# pse84 register map
Vendor: Cypress Semiconductor; Series: PSE84; File version: 1.0
CPU: CM33 r0p1, little endian, MPU, FPU, VTOR, 3 interrupt priority bits
Registers are 32-bit, read-write, reset 0x0 unless marked. A register's access mark holds for its fields unless they carry their own. Offsets are from the block's base; [hi:lo] are bit positions; lines under a group give offsets from that group; {n}, {i} and the like mark numbered series.

## ACTRLR (part 2 of 3) — Autonomnous Controller
Base 0x42ED0000
{0x800+0x20*i} TTCFG[{i}] (i=0..63) group — Timer Table Structure (only accessible if CTRL.EN=0)
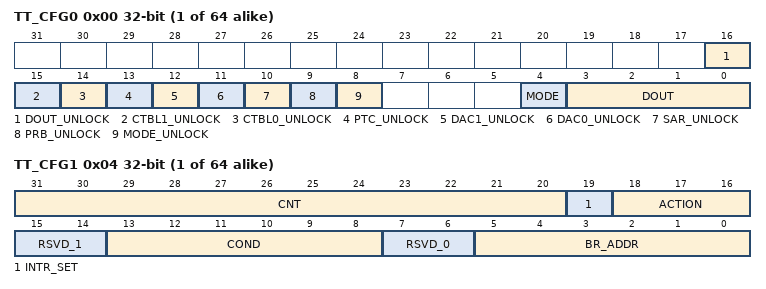
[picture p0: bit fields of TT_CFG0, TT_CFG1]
  0x00 TT_CFG0 — AC Table Configuration 0
    [16] DOUT_UNLOCK — DOUT Unlock 0: Lock: DOUT does NOT get updated 1: Unlock: DOUT does get updated
    [15] CTBL1_UNLOCK — See CTBL0_UNLOCK
    [14] CTBL0_UNLOCK — CTBL0 Unlock 0: Lock: CTBL0 fields: OPA1(0)_EN, OPA1(0)_GAIN, OPA1(0)_CFG do NOT get updated 1: Unlock: CTBL0 fields: OPA1(0)_EN, OPA1(0)_GAIN, OPA1(0)_CFG do get updated
    [13] PTC_UNLOCK — PTC Unlock 0: Lock: PTC fields: CMP1(0)_EN, CMP1(0)_CFG do NOT get updated 1: Unlock: PTC fields: CMP1(0)_EN, CMP1(0)_CFG do get updated
    [12] DAC1_UNLOCK — See DAC0_UNLOCK
    [11] DAC0_UNLOCK — DAC0 Unlock 0: Lock: DAC0 fields: EN does NOT get updated 1: Unlock: DAC0 fields: EN does get updated
    [10] SAR_UNLOCK — SAR Unlock 0: Lock: SAR fields: EN does NOT get updated 1: Unlock: SAR fields: EN does get updated
    [9] PRB_UNLOCK — PRB Unlock 0: Lock: PRB fields: VREF1(0)_VAL, VREF1(0)_FW_MODE do NOT get updated 1: Unlock: PRB fields: VREF1(0)_VAL, VREF1(0)_FW_MODE do get updated
    [8] MODE_UNLOCK — Mode Unlock 0: Lock: MODE does NOT get updated 1: Unlock: MODE does get updated
    [4] MODE — LPPASS Operating Mode 0: High Speed (HS) Operation - The PASS is clocked from CLK_HF directly (nominally 80MHz) and is only functional in chip Active mode (i.e. the IP is reset in chip Deepsleep and Hibernate) 1: Low Power (LP) Operation - The PASS is clocked from CLK_LPOSC (4MHz) and is functional in chip Active and Deepsleep mode (i.e. the IP is only reset in Hibernate)
    [3:0] DOUT — LPPASS data out generation (the corresponding bit in CFG.DOUT_EN must be set when using this field) The data out bus is driven directly to the GPIO HSIO interface. The HSIO interface must be programmed properly for the DOUT bus to be observed on the GPIO pins.
  0x04 TT_CFG1 — AC Table Configuration 1
    [31:20] CNT — This field is used to set the timer/counter values for either interval and loop counts. The actual count is CNT+1. Therefore, the range is 1 to 4096. The value of 1 is degenerate. This field is only valid if the action (ACT) is set to WAIT_FOR, or BRANCH_IF_* and the condition (COND) is set to CNT_DONE. If ACT is set to WAIT_FOR, the counter is first loaded with CNT+1 and is subsequently decremented every clock cycle (clock set by MODE). On terminal count, the CNT_DONE trigger is asserted. If ACT is set to BRANCH_IF_*, the counter is first checked if it is busy (count value is nonzero). If busy, the counter is decremented. If not busy, the counter is loaded with CNT+1. On terminal count, the CNT_DONE trigger is asserted.
    [19] INTR_SET — AC Interrupt Set This field is used for setting the Autonomous Controller Interrupt and/or trigger. When set in a particular state, the AC generates a single cycle pulse to the interrupt logic. The AC interrupt or AC trigger must be unmasked for this field to generate an interrupt/trigger. If ACTION=WAIT_FOR, the signle cycle pulse is generated after the COND occurs, otherwise the single cycle pulse is sent immediately upon entering the state where the field is set.
    [18:16] ACTION — Autonomous Controller Action
      0=STOP (Stop the autonomous controller); 1=NEXT (Proceed to the next state); 2=WAIT_FOR (Wait for the associated COND to occur before moving to the next state If COND=FALSE, stay in the present state indefinitely. If COND=TRUE, move to the next state.); 3=BRANCH_IF_TRUE (Check if COND has occurred, If it has, take the indicated branch (BR ADDR), if not, proceed to the next state. If COND=FALSE, proceed to the next state. If COND=TRUE, take the indicated branch (BR_ADDR).); 4=BRANCH_IF_FALSE (Check if COND has occurred, If it has proceed to the next state, if not, take the indicated branch (BR ADDR) If COND=FALSE, take the indicated branch (BR_ADDR). If COND=TRUE, proceed to the next state.); 5=BRANCH_IF_TRUE_CLR (Check if COND has occurred, If it has, take the indicated branch (BR ADDR), if not, proceed to the next state. If COND=FALSE, proceed to the next state. If COND=TRUE, take the indicated branch (BR_ADDR). If the indicated branch is taken, all loop counters are cleared (reset). If the AC_CONDITION is set to CNT_DONE, then the loop counters are not cleared (reset).); 6=BRANCH_IF_FALSE_CLR (Check if COND has occurred, If it has proceed to the next state, if not, take the indicated branch (BR ADDR) If COND=FALSE, take the indicated branch (BR_ADDR). If COND=TRUE, proceed to the next state. If the indicated branch is taken, all loop counters are cleared (reset). If the AC CONDITION is set to CNT_DONE, then the loop counters are not cleared (reset).); 7=RSVD0 (N/A)
    [15:14] RSVD_1
    [13:8] COND — Autonomous Controller Condition
      0=False (Hardcoded FALSE value); 1=True (Hardcoded TRUE value); 2=BLOCK_READY (Enabled block(s) are ready for use.); 3=CNT_DONE (if the ACTION is WAIT_FOR - this is an interval timer. If the ACTION is BRANCH IF - this is a loop counter.); 4=SAR_DONE (SAR Sequencer Done This status is sticky. It is set by the SAR when finishing a state in the SAR sequencer table (HS or LP) where SAR.SEQ_HS(LP)_DATA.NEXT_STATE is set to STOP. This field should NOT be used if the SAR is configured for CONTINUOUS operation (i.e. SAR.SEQ_HS(LP)_DATA.NEXT_STATE is set to GO_TO_ENTRY_ADDRESS). The status is cleared by the AC when any of the following occur: 1. Executing an AC state where ACT is set to WAIT_FOR or BRANCH_IF_* and COND is set to SAR_DONE. 2. Executing an AC state where ACT is set to WAIT_FOR and COND is set to any of the *_WAKE. 3. Pausing the AC (using the DEBUG_PAUSE or DEBUG_SINGLE_STEP commands) 4. Disabling the AC (through CTRL.ENABLED) 5. Disabling the SAR (by clearing TT_CFG3.SAR_EN) No overflow indication is provided for this bit. Therefore, it is up to the user to program the AC such that this status is read prior to an overflow (multiple SAR_DONEs). This status does NOT indicate that the SAR data has been written to the FIFO (indicated by SAR_FIFO_DONE).); 5=SAR_EOS (SAR Sequencer EOS This status is sticky. It is set by the SAR when finishing the state in the SAR sequencer table (HS or LP) where SAR.SEQ_HS(LP)_DATA.NEXT_STATE is set to GO_TO_ENTRY_ADDRESS or STOP. The status is cleared by the AC when executing an AC state with the COND programmed to SAR_EOS. No overflow indication is provided for this bit. Therefore, it is up to the user to program the AC such that this status is read prior to an overflow (multiple SAR_EOSs). The status is cleared by the AC when any of the following occur: 1. Executing an AC state where ACT is set to WAIT_FOR or BRANCH_IF_* and COND is set to SAR_EOS. 2. Executing an AC state where ACT is set to WAIT_FOR and COND is set to any of the *_WAKE. 3. Pausing the AC (using the DEBUG_PAUSE or DEBUG_SINGLE_STEP commands) 4. Disabling the AC (through CTRL.ENABLED) 5. Disabling the SAR (by clearing TT_CFG3.SAR_EN) No overflow indication is provided for this bit. Therefore, it is up to the user to program the AC such that this status is read prior to an overflow (multiple SAR_EOSs).); 6=SAR_RANGE0 (SAR Range 0 detection This status is sticky. It is set by the SAR if the RANGE0 condition is met for a given channel with range 0 status enabled (i.e. SAR_STA_CFG.GPIO(MUX)_CHAN_CFG.STATUS_SEL=STATUS_STRUCT_0). The status is cleared by the AC when any of the following occur: 1. Executing an AC state where ACT is set to WAIT_FOR or BRANCH_IF_* and COND is set to SAR_RANGE0. 2. Executing an AC state where ACT is set to WAIT_FOR and COND is set to any of the *_WAKE. 3. Pausing the AC (using the DEBUG_PAUSE or DEBUG_SINGLE_STEP commands) 4. Disabling the AC (through CTRL.ENABLED) 5. Disabling the SAR (by clearing TT_CFG3.SAR_EN) No overflow indication is provided for this bit. Therefore, it is up to the user to program the AC such that this status is read prior to an overflow (multiple SAR_RANGE0s).); 7=SAR_RANGE1 (SAR Range 1 detection This status is sticky. It is set by the SAR if the RANGE0 condition is met for a given channel with range 1 status enabled (i.e. SAR_STA_CFG.GPIO(MUX)_CHAN_CFG.STATUS_SEL=STATUS_STRUCT_1). The status is cleared by the AC when any of the following occur: 1. Executing an AC state where ACT is set to WAIT_FOR or BRANCH_IF_* and COND is set to SAR_RANGE1. 2. Executing an AC state where ACT is set to WAIT_FOR and COND is set to any of the *_WAKE. 3. Pausing the AC (using the DEBUG_PAUSE or DEBUG_SINGLE_STEP commands) 4. Disabling the AC (through CTRL.ENABLED) 5. Disabling the SAR (by clearing TT_CFG3.SAR_EN) No overflow indication is provided for this bit. Therefore, it is up to the user to program the AC such that this status is read prior to an overflow (multiple SAR_RANGE0s).); 8=SAR_RANGE2 (SAR Range 2 detection This status is sticky. It is set by the SAR if the RANGE2 condition is met for a given channel with range 0 status enabled (i.e. SAR_STA_CFG.GPIO(MUX)_CHAN_CFG.STATUS_SEL=STATUS_STRUCT_2). The status is cleared by the AC when any of the following occur: 1. Executing an AC state where ACT is set to WAIT_FOR or BRANCH_IF_* and COND is set to SAR_RANGE2. 2. Executing an AC state where ACT is set to WAIT_FOR and COND is set to any of the *_WAKE. 3. Pausing the AC (using the DEBUG_PAUSE or DEBUG_SINGLE_STEP commands) 4. Disabling the AC (through CTRL.ENABLED) 5. Disabling the SAR (by clearing TT_CFG3.SAR_EN) No overflow indication is provided for this bit. Therefore, it is up to the user to program the AC such that this status is read prior to an overflow (multiple SAR_RANGE2s).); 9=SAR_RANGE3 (SAR Range 3 detection This status is sticky. It is set by the SAR if the RANGE0 condition is met for a given channel with range 3 status enabled (i.e. SAR_STA_CFG.GPIO(MUX)_CHAN_CFG.STATUS_SEL=STATUS_STRUCT_3). The status is cleared by the AC when any of the following occur: 1. Executing an AC state where ACT is set to WAIT_FOR or BRANCH_IF_* and COND is set to SAR_RANGE3. 2. Executing an AC state where ACT is set to WAIT_FOR and COND is set to any of the *_WAKE. 3. Pausing the AC (using the DEBUG_PAUSE or DEBUG_SINGLE_STEP commands) 4. Disabling the AC (through CTRL.ENABLED) 5. Disabling the SAR (by clearing TT_CFG3.SAR_EN) No overflow indication is provided for this bit. Therefore, it is up to the user to program the AC such that this status is read prior to an overflow (multiple SAR_RANGE3s).); 10=SAR_BUSY (SAR BUSY detection This status is set whenever the SAR is running a scan. This status is transparent from the SAR sequencer (i.e. the status is not sticky).); 11=SAR_FIR0_DONE (SAR FIR0 Done detection This status is sticky. It is set by the SAR FIR0 block whenever FIR0 produces a valid output. The status is cleared by the AC when any of the following occur: 1. Executing an AC state where ACT is set to WAIT_FOR or BRANCH_IF_* and COND is set to SAR_RANGE3. 2. Executing an AC state where ACT is set to WAIT_FOR and COND is set to any of the *_WAKE. 3. Pausing the AC (using the DEBUG_PAUSE or DEBUG_SINGLE_STEP commands) 4. Disabling the AC (through CTRL.ENABLED) 5. Disabling the SAR (by clearing TT_CFG3.SAR_EN) The status is cleared by the AC when executing an AC state with the COND programmed to SAR_FIR0_DONE. No overflow indication is provided for this bit. Therefore, it is up to the user to program the AC such that this status is read prior to an overflow (multiple SAR_FIR0_DONEs). This status does NOT indicate that the FIR0 data has been written to the FIFO (indicated by SAR_FIR0_FIFO_DONE).); 12=SAR_FIR1_DONE (SAR FIR1 Done detection This status is sticky. It is set by the SAR FIR1 block whenever FIR0 produces a valid output. The status is cleared by the AC when any of the following occur: 1. Executing an AC state where ACT is set to WAIT_FOR or BRANCH_IF_* and COND is set to SAR_RANGE3. 2. Executing an AC state where ACT is set to WAIT_FOR and COND is set to any of the *_WAKE. 3. Pausing the AC (using the DEBUG_PAUSE or DEBUG_SINGLE_STEP commands) 4. Disabling the AC (through CTRL.ENABLED) 5. Disabling the SAR (by clearing TT_CFG3.SAR_EN) The status is cleared by the AC when executing an AC state with the COND programmed to SAR_FIR1_DONE. No overflow indication is provided for this bit. Therefore, it is up to the user to program the AC such that this status is read prior to an overflow (multiple SAR_FIR1_DONEs). This status does NOT indicate that the FIR1 data has been written to the FIFO (indicated by SAR_FIR1_FIFO_DONE).); 13=SAR_FIFO_DONE (SAR FIFO Done This status is sticky. This status is SAR_DONE ANDED with FIFO writing complete. This field should NOT be used if the SAR is configured for CONTINUOUS operation (i.e. SAR.SEQ_HS(LP)_DATA.NEXT_STATE is set to GO_TO_ENTRY_ADDRESS) since SAR_DONE is never asserted. In that case, the user should use the appropriate FIFO_LEVEL triggers. The status is cleared by the AC when any of the following occur: 1. Executing an AC state where ACT is set to WAIT_FOR or BRANCH_IF_* and COND is set to SAR_FIFO_DONE. 2. Executing an AC state where ACT is set to WAIT_FOR and COND is set to any of the *_WAKE. 3. Pausing the AC (using the DEBUG_PAUSE or DEBUG_SINGLE_STEP commands) 4. Disabling the AC (through CTRL.ENABLED) 5. Disabling the SAR (by clearing TT_CFG3.SAR_EN) No overflow indication is provided for this bit. Therefore, it is up to the user to program the AC such that this status is read prior to an overflow (multiple SAR_FIFO_DONEs). This status does NOT indicate that the SAR data has been written to the FIFO (indicated by SAR_FIFO_DONE).); 14=SAR_FIR0_FIFO_DONE (SAR FIR0 FIFO Done detection This status is sticky. It is set by the SAR FIR0 block whenever FIR0 data has been written into the FIFO. When using this bit, it is expected that FIR0 writes to the FIFO only once in a given SAR scan. The status is cleared by the AC when any of the following occur: 1. Executing an AC state where ACT is set to WAIT_FOR or BRANCH_IF_* and COND is set to SAR_FIR0_FIFO_DONE. 2. Executing an AC state where ACT is set to WAIT_FOR and COND is set to any of the *_WAKE. 3. Pausing the AC (using the DEBUG_PAUSE or DEBUG_SINGLE_STEP commands) 4. Disabling the AC (through CTRL.ENABLED) 5. Disabling the SAR (by clearing TT_CFG3.SAR_EN) No overflow indication is provided for this bit. Therefore, it is up to the user to program the AC such that this status is read prior to an overflow (multiple SAR_FIR0_FIFO_DONEs).); 15=SAR_FIR1_FIFO_DONE (SAR FIR1 FIFO Done detection This status is sticky. It is set by the SAR FIR1 block whenever FIR1 data has been written into the FIFO. When using this bit, it is expected that FIR1 writes to the FIFO only once in a given SAR scan. The status is cleared by the AC when any of the following occur: 1. Executing an AC state where ACT is set to WAIT_FOR or BRANCH_IF_* and COND is set to SAR_FIR1_FIFO_DONE. 2. Executing an AC state where ACT is set to WAIT_FOR and COND is set to any of the *_WAKE. 3. Pausing the AC (using the DEBUG_PAUSE or DEBUG_SINGLE_STEP commands) 4. Disabling the AC (through CTRL.ENABLED) 5. Disabling the SAR (by clearing TT_CFG3.SAR_EN) No overflow indication is provided for this bit. Therefore, it is up to the user to program the AC such that this status is read prior to an overflow (multiple SAR_FIR1_FIFO_DONEs).); 16=PTC_STROBE0 (PTC Post Processor 0 Strobe This status is set whenever the PTC Post Processor 0 has valid data. This status is transparent from the PTC post processor (i.e. the status is not sticky). The AC needs to poll this status (i.e. ACTION is WAIT_FOR and COND is PTC_STROBE0) prior to checking PTC_RANGE0.); 17=PTC_STROBE1 (PTC Post Processor 1 Strobe This status is set whenever the PTC Post Processor 1 has valid data. This status is transparent from the PTC post processor (i.e. the status is not sticky). The AC needs to poll this status (i.e. ACTION is WAIT_FOR and COND is PTC_STROBE1) prior to checking PTC_RANGE1.); 18=PTC_CMP0 (PTC COMP0 output This status is sticky. It is set by the PTC Comparator 0 if the condition is met (i.e. PTC_STA_CFG.CFG.COMP0_OUT field). The status is cleared by the AC when any of the following occur: 1. Executing an AC state where ACT is set to WAIT_FOR or BRANCH_IF_* and COND is set to PTC_CMP0. 2. Executing an AC state where ACT is set to WAIT_FOR and COND is set to any of the *_WAKE. 3. Pausing the AC (using the DEBUG_PAUSE or DEBUG_SINGLE_STEP commands) 4. Disabling the AC (through CTRL.ENABLED) 5. Disabling PTC comparator 1 (by clearing TT_CFG3.PTC_CMP0_EN) No overflow indication is provided for this bit. Therefore, it is up to the user to program the AC such that this status is read prior to an overflow (multiple PTC_CMP0s).); 19=PTC_CMP1 (PTC COMP1 output This status is sticky. It is set by the PTC Comparator 1 if the condition is met (i.e. PTC_STA_CFG.CFG.COMP1_OUT field). The status is cleared by the AC when any of the following occur: 1. Executing an AC state where ACT is set to WAIT_FOR or BRANCH_IF_* and COND is set to PTC_CMP1. 2. Executing an AC state where ACT is set to WAIT_FOR and COND is set to any of the *_WAKE. 3. Pausing the AC (using the DEBUG_PAUSE or DEBUG_SINGLE_STEP commands) 4. Disabling the AC (through CTRL.ENABLED) 5. Disabling PTC comparator 1 (by clearing TT_CFG3.PTC_CMP1_EN) No overflow indication is provided for this bit. Therefore, it is up to the user to program the AC such that this status is read prior to an overflow (multiple PTC_CMP1s).); 20=PTC_RANGE0 (PTC Post Processor 0 Range output This status is sticky. It is set by the PTC Post Processor if the RANGE0 condition is met (i.e. PTC_PP_STRUCT0.*). The status is cleared by the AC when any of the following occur: 1. Executing an AC state where ACT is set to WAIT_FOR or BRANCH_IF_* and COND is set to SAR_FIR1_FIFO_DONE. 2. Executing an AC state where ACT is set to WAIT_FOR and COND is set to any of the *_WAKE. 3. Pausing the AC (using the DEBUG_PAUSE or DEBUG_SINGLE_STEP commands) 4. Disabling the AC (through CTRL.ENABLED) 5. Disabling both PTC comparators (by clearing TT_CFG3.PTC_CMP0_EN AND TT_CFG3_PTC_COMP1_EN) No overflow indication is provided for this bit. Therefore, it is up to the user to program the AC such that this status is read prior to an overflow (multiple PTC_RANGE0s).); 21=PTC_RANGE1 (PTC Post Processor 1 Range output This status is sticky. It is set by the PTC Post Processor if the RANGE1 condition is met (i.e. PTC_PP_STRUCT1.*). The status is cleared by the AC when any of the following occur: 1. Executing an AC state where ACT is set to WAIT_FOR or BRANCH_IF_* and COND is set to SAR_FIR1_FIFO_DONE. 2. Executing an AC state where ACT is set to WAIT_FOR and COND is set to any of the *_WAKE. 3. Pausing the AC (using the DEBUG_PAUSE or DEBUG_SINGLE_STEP commands) 4. Disabling the AC (through CTRL.ENABLED) 5. Disabling both PTC comparators (by clearing TT_CFG3.PTC_CMP0_EN AND TT_CFG3_PTC_COMP1_EN) No overflow indication is provided for this bit. Therefore, it is up to the user to program the AC such that this status is read prior to an overflow (multiple PTC_RANGE1s).); 22=CTBL0_CMP0 (CTBL0 COMP0 output This status is sticky. It is set by the CTBL0 Opamp0 Comparator if the condition is met (i.e. CTBL_STA_CFG.CFG.COMP0_OUT field). The status is cleared by the AC when any of the following occur: 1. Executing an AC state where ACT is set to WAIT_FOR or BRANCH_IF_* and COND is set to CTBL0_CMP0. 2. Executing an AC state where ACT is set to WAIT_FOR and COND is set to any of the *_WAKE. 3. Pausing the AC (using the DEBUG_PAUSE or DEBUG_SINGLE_STEP commands) 4. Disabling the AC (through CTRL.ENABLED) 5. Disabling CTBL0 opamp0 (by clearing TT_CFG2.CTBL0_OA0_EN) No overflow indication is provided for this bit. Therefore, it is up to the user to program the AC such that this status is read prior to an overflow (multiple CTBL0_CMP0s).); 23=CTBL0_CMP1 (CTBL0 COMP1 output This status is sticky. It is set by the CTBL0 Opamp1 Comparator if the condition is met (i.e. CTBL_STA_CFG.CFG.COMP1_OUT field). The status is cleared by the AC when any of the following occur: 1. Executing an AC state where ACT is set to WAIT_FOR or BRANCH_IF_* and COND is set to CTBL0_CMP1. 2. Executing an AC state where ACT is set to WAIT_FOR and COND is set to any of the *_WAKE. 3. Pausing the AC (using the DEBUG_PAUSE or DEBUG_SINGLE_STEP commands) 4. Disabling the AC (through CTRL.ENABLED) 5. Disabling CTBL0 opamp1 (by clearing TT_CFG2.CTBL0_OA1_EN) No overflow indication is provided for this bit. Therefore, it is up to the user to program the AC such that this status is read prior to an overflow (multiple CTBL0_CMP1s).); 24=CTBL1_CMP0 (CTBL1 COMP0 output This status is sticky. It is set by the CTBL1 Opamp0 Comparator if the condition is met (i.e. CTBL_STA_CFG.CFG.COMP0_OUT field). The status is cleared by the AC when any of the following occur: 1. Executing an AC state where ACT is set to WAIT_FOR or BRANCH_IF_* and COND is set to CTBL1_CMP0. 2. Executing an AC state where ACT is set to WAIT_FOR and COND is set to any of the *_WAKE. 3. Pausing the AC (using the DEBUG_PAUSE or DEBUG_SINGLE_STEP commands) 4. Disabling the AC (through CTRL.ENABLED) 5. Disabling CTBL1 opamp0 (by clearing TT_CFG2.CTBL0_OA0_EN) No overflow indication is provided for this bit. Therefore, it is up to the user to program the AC such that this status is read prior to an overflow (multiple CTBL1_CMP0s).); 25=CTBL1_CMP1 (CTBL1 COMP1 output This status is sticky. It is set by the CTBL1 Opamp1 Comparator if the condition is met (i.e. CTBL_STA_CFG.CFG.COMP1_OUT field). The status is cleared by the AC when any of the following occur: 1. Executing an AC state where ACT is set to WAIT_FOR or BRANCH_IF_* and COND is set to CTBL1_CMP1. 2. Executing an AC state where ACT is set to WAIT_FOR and COND is set to any of the *_WAKE. 3. Pausing the AC (using the DEBUG_PAUSE or DEBUG_SINGLE_STEP commands) 4. Disabling the AC (through CTRL.ENABLED) 5. Disabling CTBL1 opamp1 (by clearing TT_CFG2.CTBL0_OA1_EN) No overflow indication is provided for this bit. Therefore, it is up to the user to program the AC such that this status is read prior to an overflow (multiple CTBL1_CMP1s).); {v}=RSVD{v-26} (N/A) (v=26..31); 32=CHIP_ACTIVE_MODE (Chip Active Mode Status This status is set whenever the system is operating in Active Mode (this includes all Low Power active modes)); 33=CHIP_DEEPSLEEP_MODE (Chip Deepsleep Mode Status This status is set whenever the system is operating in Deepsleep Mode (this includes all RAM power modes in Deepsleep)); {v}=TR_LPPASS_IN{v-34} (External trigger 0 (or the FW trigger {v-34}) This status is sticky. It is set by the either the external hardware trigger 0 or FW trigger {v-34} asserting. The status is cleared by the AC when any of the following occur: 1. Executing an AC state where ACT is set to WAIT_FOR or BRANCH_IF_* and COND is set to TR_LPPASS_IN{v-34}. 2. Executing an AC state where ACT is set to WAIT_FOR and COND is set to any of the *_WAKE. 3. Pausing the AC (using the DEBUG_PAUSE or DEBUG_SINGLE_STEP commands) 4. Disabling the AC (through CTRL.ENABLED) No overflow indication is provided for this bit. Therefore, it is up to the user to program the AC such that this status is read prior to an overflow (multiple TR_LPPASS_IN{v-34}s).) (v=34..37); 38=TR_LPPASS_IN_WAKE (External Trigger Wakeup Source When using this condition, the action (ACT) must be set to WAIT_FOR. This condition is used to put the AC to sleep. The AC will wake from sleep when any external trigger [0-3] is asserted. When the AC is sleeping, all registered AC conditions are cleared.); 39=TIMER_DONE_WAKE (Timer Wakeup Source When using this condition, the action (ACT) must be set to WAIT_FOR. The Wakeup Timer must also be configured (INFRA.TIMER registers). This condition is used to put the AC to sleep. The AC will wake from sleep when the Wakeup Timer reaches terminal count (TC). When the AC is sleeping, all registered AC conditions are cleared.); 40=CTBL0_CMP0_WAKE (CTBL0 comparator 0 wakeup When using this condition, the action (ACT) must be set to WAIT_FOR. The comparator wakeup condition is configured per CTBL0_STA_CFG_Regs.CFG.OA0_COMP_OUT. The CTBL0 comparator 0 be enabled during sleep (TT_CFG2.CTBL0_OA0_EN=1). This condition is used to put the AC to sleep. The AC will wake from sleep when CTBL0 Comparator 0 meets the configured wakeup condition. When the AC is sleeping, all registered AC conditions are cleared.); 41=CTBL0_CMP1_WAKE (CTBL0 comparator 1 wakeup When using this condition, the action (ACT) must be set to WAIT_FOR. The comparator wakeup condition is configured per CTBL0_STA_CFG_Regs.CFG.OA0_COMP_OUT. The CTBL0 comparator 1 be enabled during sleep (TT_CFG2.CTBL0_OA1_EN=1). This condition is used to put the AC to sleep. The AC will wake from sleep when CTBL0 Comparator 1 meets the configured wakeup condition. When the AC is sleeping, all registered AC conditions are cleared.); 42=CTBL1_CMP0_WAKE (CTBL1 comparator 0 wakeup When using this condition, the action (ACT) must be set to WAIT_FOR. The comparator wakeup condition is configured per CTBL1_STA_CFG_Regs.CFG.OA0_COMP_OUT. The CTBL1 comparator 0 be enabled during sleep (TT_CFG2.CTBL1_OA0_EN=1). This condition is used to put the AC to sleep. The AC will wake from sleep due when CTBL1 Comparator 0 meets the configured wkaeup condition. When the AC is sleeping, all registered AC conditions are cleared.); 43=CTBL1_CMP1_WAKE (CTBL1 comparator 1 wakeup When using this condition, the action (ACT) must be set to WAIT_FOR. The comparator wakeup condition is configured per CTBL1_STA_CFG_Regs.CFG.OA0_COMP_OUT. The CTBL1 comparator 1 be enabled during sleep (TT_CFG2.CTBL1_OA1_EN=1). This condition is used to put the AC to sleep. The AC will wake from sleep when CTBL1 Comparator 1 meets the configured wakeup condition. When the AC is sleeping, all registered AC conditions are cleared.); 44=PTC_CMP0_WAKE (PTC comparator 0 wakeup When using this condition, the action (ACT) must be set to WAIT_FOR. The comparator wakeup condition is configured per PTC_STA_CFG_Regs.CFG.COMP0_OUT. The PTC comparator 0 be enabled during sleep (TT_CFG3.PTC_CMP0_EN=1). This condition is used to put the AC to sleep. The AC will wake from sleep when PTC Comparator 0 meets the configured wakeup condition. When the AC is sleeping, all registered AC conditions are cleared.); 45=PTC_CMP1_WAKE (PTC comparator 1 wakeup When using this condition, the action (ACT) must be set to WAIT_FOR. The comparator wakeup condition is configured per PTC_STA_CFG_Regs.CFG.COMP1_OUT. The PTC comparator 0 be enabled during sleep (TT_CFG3.PTC_CMP1_EN=1). This condition is used to put the AC to sleep. The AC will wake from sleep when PTC Comparator 1 meets the configured wakeup condition. When the AC is sleeping, all registered AC conditions are cleared.); 46=FIFO_LEVEL0 (FIFO Level 0 trigger This status is set whenever FIFO0 level condition has been met (FIFO_LEVEL0.LEVEL). This status is transparent from the FIFO (i.e. the status is not sticky).); 47=FIFO_LEVEL1 (FIFO Level 1 trigger This status requires that FIFO_STA_CFG_Regs.CFG.SEL=1,2,3. This status is set whenever FIFO1 level condition has been met (FIFO_LEVEL1.LEVEL). This status is transparent from the FIFO (i.e. the status is not sticky).); 48=FIFO_LEVEL2 (FIFO Level 2 trigger This status requires that FIFO_STA_CFG_Regs.CFG.SEL=2,3. This status is set whenever FIFO2 level condition has been met (FIFO_LEVEL2.LEVEL). This status is transparent from the FIFO (i.e. the status is not sticky).); 49=FIFO_LEVEL3 (FIFO Level 3 trigger This status requires that FIFO_STA_CFG_Regs.CFG.SEL=2,3. This status is set whenever FIFO3 level condition has been met (FIFO_LEVEL3.LEVEL). This status is transparent from the FIFO (i.e. the status is not sticky).); {v}=FIFO_LEVEL{v-46} (FIFO Level {v-46} trigger This status requires that FIFO_STA_CFG_Regs.CFG.SEL=3. This status is set whenever FIFO{v-46} level condition has been met (FIFO_LEVEL{v-46}.LEVEL). This status is transparent from the FIFO (i.e. the status is not sticky).) (v=50..53); 54=DAC0_RANGE0 (DAC0 Range 0 detection This status is sticky. It is set by the DAC0 if the RANGE0 condition is met for a given channel with range 0 status enabled (i.e. DAC0_STA_CFG.CHAN_CFG.STATUS_SEL=STATUS_0). This status is not used when DAC0 is configured for FW mode. The status is cleared by the AC when any of the following occur: 1. Executing an AC state where ACT is set to WAIT_FOR or BRANCH_IF_* and COND is set to DAC0_RANGE0. 2. Executing an AC state where ACT is set to WAIT_FOR and COND is set to any of the *_WAKE. 3. Pausing the AC (using the DEBUG_PAUSE or DEBUG_SINGLE_STEP commands) 4. Disabling the AC (through CTRL.ENABLED) 5. Disabling the DAC0 (by clearing TT_CFG3.DAC0_EN) No overflow indication is provided for this bit. Therefore, it is up to the user to program the AC such that this status is read prior to an overflow (multiple DAC0_RANGE0s).); 55=DAC0_RANGE1 (DAC0 Range 1 detection This status is sticky. It is set by the DAC0 if the RANGE1 condition is met for a given channel with range 1 status enabled (i.e. DAC0_STA_CFG.CHAN_CFG.STATUS_SEL=STATUS_1). This status is not used when DAC0 is configured for FW mode. The status is cleared by the AC when any of the following occur: 1. Executing an AC state where ACT is set to WAIT_FOR or BRANCH_IF_* and COND is set to DAC0_RANGE1. 2. Executing an AC state where ACT is set to WAIT_FOR and COND is set to any of the *_WAKE. 3. Pausing the AC (using the DEBUG_PAUSE or DEBUG_SINGLE_STEP commands) 4. Disabling the AC (through CTRL.ENABLED) 5. Disabling the DAC0 (by clearing TT_CFG3.DAC0_EN) No overflow indication is provided for this bit. Therefore, it is up to the user to program the AC such that this status is read prior to an overflow (multiple DAC0_RANGE1s).); 56=DAC0_RANGE2 (DAC0 Range 2 detection This status is sticky. It is set by the DAC0 if the RANGE2 condition is met for a given channel with range 2 status enabled (i.e. DAC0_STA_CFG.CHAN_CFG.STATUS_SEL=STATUS_2). This status is not used when DAC0 is configured for FW mode. The status is cleared by the AC when any of the following occur: 1. Executing an AC state where ACT is set to WAIT_FOR or BRANCH_IF_* and COND is set to DAC0_RANGE2. 2. Executing an AC state where ACT is set to WAIT_FOR and COND is set to any of the *_WAKE. 3. Pausing the AC (using the DEBUG_PAUSE or DEBUG_SINGLE_STEP commands) 4. Disabling the AC (through CTRL.ENABLED) 5. Disabling the DAC0 (by clearing TT_CFG3.DAC0_EN) No overflow indication is provided for this bit. Therefore, it is up to the user to program the AC such that this status is read prior to an overflow (multiple DAC0_RANGE2s).); 57=DAC0_EPOCH (DAC0 End of Waveform event This status is sticky. It is set by the DAC when finishing a waveform. This condition is only used if the DAC channel (pointed to by the AC when triggered) is configured for LUT mode. The status is cleared by the AC when any of the following occur: 1. Executing an AC state where ACT is set to WAIT_FOR or BRANCH_IF_* and COND is set to DAC0_EPOCH. 2. Executing an AC state where ACT is set to WAIT_FOR and COND is set to any of the *_WAKE. 3. Pausing the AC (using the DEBUG_PAUSE or DEBUG_SINGLE_STEP commands) 4. Disabling the AC (through CTRL.ENABLED) 5. Disabling the SAR (by clearing TT_CFG3.DAC0_EN) No overflow indication is provided for this bit. Therefore, it is up to the user to program the AC such that this status is read prior to an overflow (multiple DAC0_EPOCHs).); 58=DAC0_STROBE (DAC0 Strobe This status is set whenever the DAC output has been updated. This status is typically used by the AC to poll when the DAC has responded to the DAC_INC/DAC_DEC fields.This status is transparent from the DAC (i.e. the status is not sticky). The AC needs to poll this status (i.e. ACTION is WAIT_FOR and COND is DAC0_STROBE) prior to checking DAC_RANGE0-2 or setting DAC_INC/DAC_DEC fields.); 59=DAC1_RANGE0 (DAC1 Range 0 detection This status is sticky. It is set by the DAC1 if the RANGE0 condition is met for a given channel with range 0 status enabled (i.e. DAC1_STA_CFG.CHAN_CFG.STATUS_SEL=STATUS_0). The status is cleared by the AC when any of the following occur: 1. Executing an AC state where ACT is set to WAIT_FOR or BRANCH_IF_* and COND is set to DAC1_RANGE0. 2. Executing an AC state where ACT is set to WAIT_FOR and COND is set to any of the *_WAKE. 3. Pausing the AC (using the DEBUG_PAUSE or DEBUG_SINGLE_STEP commands) 4. Disabling the AC (through CTRL.ENABLED) 5. Disabling the DAC1 (by clearing TT_CFG3.DAC1_EN) No overflow indication is provided for this bit. Therefore, it is up to the user to program the AC such that this status is read prior to an overflow (multiple DAC1_RANGE0s).); 60=DAC1_RANGE1 (DAC1 Range 1 detection This status is sticky. It is set by the DAC0 if the RANGE1 condition is met for a given channel with range 1 status enabled (i.e. DAC1_STA_CFG.CHAN_CFG.STATUS_SEL=STATUS_1). The status is cleared by the AC when any of the following occur: 1. Executing an AC state where ACT is set to WAIT_FOR or BRANCH_IF_* and COND is set to DAC1_RANGE1. 2. Executing an AC state where ACT is set to WAIT_FOR and COND is set to any of the *_WAKE. 3. Pausing the AC (using the DEBUG_PAUSE or DEBUG_SINGLE_STEP commands) 4. Disabling the AC (through CTRL.ENABLED) 5. Disabling the DAC1 (by clearing TT_CFG3.DAC1_EN) No overflow indication is provided for this bit. Therefore, it is up to the user to program the AC such that this status is read prior to an overflow (multiple DAC1_RANGE1s).); 61=DAC1_RANGE2 (DAC1 Range 2 detection This status is sticky. It is set by the DAC1 if the RANGE2 condition is met for a given channel with range 2 status enabled (i.e. DAC1_STA_CFG.CHAN_CFG.STATUS_SEL=STATUS_2). The status is cleared by the AC when any of the following occur: 1. Executing an AC state where ACT is set to WAIT_FOR or BRANCH_IF_* and COND is set to DAC1_RANGE2. 2. Executing an AC state where ACT is set to WAIT_FOR and COND is set to any of the *_WAKE. 3. Pausing the AC (using the DEBUG_PAUSE or DEBUG_SINGLE_STEP commands) 4. Disabling the AC (through CTRL.ENABLED) 5. Disabling the DAC1 (by clearing TT_CFG3.DAC1_EN) No overflow indication is provided for this bit. Therefore, it is up to the user to program the AC such that this status is read prior to an overflow (multiple DAC1_RANGE2s).); 62=DAC1_EPOCH (DAC1 End of Waveform event This status is sticky. It is set by the DAC when finishing a waveform. This condition is only used if the DAC channel (pointed to by the AC when triggered) is configured for LUT mode. The status is cleared by the AC when any of the following occur: 1. Executing an AC state where ACT is set to WAIT_FOR or BRANCH_IF_* and COND is set to DAC1_EPOCH. 2. Executing an AC state where ACT is set to WAIT_FOR and COND is set to any of the *_WAKE. 3. Pausing the AC (using the DEBUG_PAUSE or DEBUG_SINGLE_STEP commands) 4. Disabling the AC (through CTRL.ENABLED) 5. Disabling the SAR (by clearing TT_CFG3.DAC1_EN) No overflow indication is provided for this bit. Therefore, it is up to the user to program the AC such that this status is read prior to an overflow (multiple DAC1_EPOCHs).); 63=DAC1_STROBE (DAC1 Strobe This status is set whenever the DAC output has been updated. This status is typically used by the AC to poll when the DAC has responded to the DAC_INC/DAC_DEC fields.This status is transparent from the DAC (i.e. the status is not sticky). The AC needs to poll this status (i.e. ACTION is WAIT_FOR and COND is DAC1_STROBE) prior to checking DAC1_RANGE0-2 or setting DAC_INC/DAC_DEC fields.)
    [7:6] RSVD_0
    [5:0] BR_ADDR — absolute address of the branch if taken (0-63 possible). This field in only used if the AC action (ACT) is set to BRANCH_IF_* and the condtion (COND) is met.
